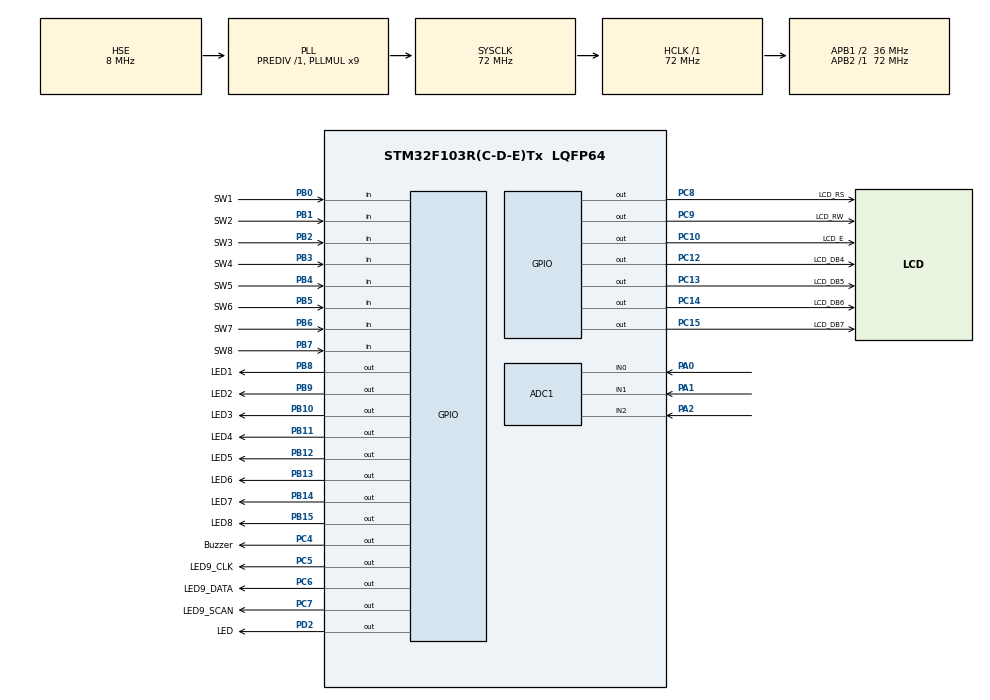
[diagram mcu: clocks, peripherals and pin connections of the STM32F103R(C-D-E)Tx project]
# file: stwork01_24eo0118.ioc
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ADC1.Channel-0\#ChannelRegularConversion=ADC_CHANNEL_0
ADC1.NbrOfConversionFlag=1
ADC1.Rank-0\#ChannelRegularConversion=1
ADC1.SamplingTime-0\#ChannelRegularConversion=ADC_SAMPLETIME_1CYCLE_5
ADC1.master=1
Mcu.Family=STM32F1
Mcu.Name=STM32F103R(C-D-E)Tx
Mcu.Package=LQFP64
NVIC.PriorityGroup=NVIC_PRIORITYGROUP_4
PA0-WKUP.Signal=ADCx_IN0
PA1.Signal=ADCx_IN1
PA13.Mode=Serial_Wire
PA13.Signal=SYS_JTMS-SWDIO
PA14.Mode=Serial_Wire
PA14.Signal=SYS_JTCK-SWCLK
PA2.Signal=ADCx_IN2
PB0.GPIO_Label=SW1
PB0.Signal=GPIO_Input
PB1.GPIO_Label=SW2
PB1.Signal=GPIO_Input
PB10.GPIO_Label=LED3
PB10.Signal=GPIO_Output
PB11.GPIO_Label=LED4
PB11.Signal=GPIO_Output
PB12.GPIO_Label=LED5
PB12.Signal=GPIO_Output
PB13.GPIO_Label=LED6
PB13.Signal=GPIO_Output
PB14.GPIO_Label=LED7
PB14.Signal=GPIO_Output
PB15.GPIO_Label=LED8
PB15.Signal=GPIO_Output
PB2.GPIO_Label=SW3
PB2.Signal=GPIO_Input
PB3.GPIO_Label=SW4
PB3.Signal=GPIO_Input
PB4.GPIO_Label=SW5
PB4.Signal=GPIO_Input
PB5.GPIO_Label=SW6
PB5.Signal=GPIO_Input
PB6.GPIO_Label=SW7
PB6.Signal=GPIO_Input
PB7.GPIO_Label=SW8
PB7.Signal=GPIO_Input
PB8.GPIO_Label=LED1
PB8.Signal=GPIO_Output
PB9.GPIO_Label=LED2
PB9.Signal=GPIO_Output
PC10.GPIO_Label=LCD_E
PC10.Signal=GPIO_Output
PC12.GPIO_Label=LCD_DB4
PC12.Signal=GPIO_Output
PC13-TAMPER-RTC.GPIO_Label=LCD_DB5
PC13-TAMPER-RTC.Signal=GPIO_Output
PC14-OSC32_IN.GPIO_Label=LCD_DB6
PC14-OSC32_IN.Signal=GPIO_Output
PC15-OSC32_OUT.GPIO_Label=LCD_DB7
PC15-OSC32_OUT.Signal=GPIO_Output
PC4.GPIO_Label=Buzzer
PC4.Signal=GPIO_Output
PC5.GPIO_Label=LED9_CLK
PC5.Signal=GPIO_Output
PC6.GPIO_Label=LED9_DATA
PC6.Signal=GPIO_Output
PC7.GPIO_Label=LED9_SCAN
PC7.Signal=GPIO_Output
PC8.GPIO_Label=LCD_RS
PC8.Signal=GPIO_Output
PC9.GPIO_Label=LCD_RW
PC9.Signal=GPIO_Output
PD0-OSC_IN.Mode=HSE-External-Oscillator
PD0-OSC_IN.Signal=RCC_OSC_IN
PD1-OSC_OUT.Mode=HSE-External-Oscillator
PD1-OSC_OUT.Signal=RCC_OSC_OUT
PD2.GPIO_Label=LED
PD2.Signal=GPIO_Output
ProjectManager.HeapSize=0x200
ProjectManager.StackSize=0x400
ProjectManager.TargetToolchain=STM32CubeIDE
RCC.ADCPresc=RCC_ADCPCLK2_DIV6
RCC.AHBFreq_Value=72000000
RCC.APB1CLKDivider=RCC_HCLK_DIV2
RCC.APB1Freq_Value=36000000
RCC.APB1TimFreq_Value=72000000
RCC.APB2Freq_Value=72000000
RCC.APB2TimFreq_Value=72000000
RCC.HCLKFreq_Value=72000000
RCC.PLLMUL=RCC_PLL_MUL9
RCC.PLLSourceVirtual=RCC_PLLSOURCE_HSE
RCC.SYSCLKFreq_VALUE=72000000
RCC.SYSCLKSource=RCC_SYSCLKSOURCE_PLLCLK
RCC.USBFreq_Value=72000000
SH.ADCx_IN0.0=ADC1_IN0,IN0
SH.ADCx_IN1.0=ADC1_IN1,IN1
SH.ADCx_IN2.0=ADC1_IN2,IN2
VP_TIM6_VS_ClockSourceINT.Mode=Enable_Timer
VP_TIM7_VS_ClockSourceINT.Mode=Enable_Timer
board=custom

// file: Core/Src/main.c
/* USER CODE BEGIN Header */
/**
  ******************************************************************************
  * @file           : main.c
  * @brief          : Main program body
  ******************************************************************************
  * @attention
  *
  * Copyright (c) 2024 STMicroelectronics.
  * All rights reserved.
  *
  * This software is licensed under terms that can be found in the LICENSE file
  * in the root directory of this software component.
  * If no LICENSE file comes with this software, it is provided AS-IS.
  *
  ******************************************************************************
  */
/* USER CODE END Header */
#include "main.h"

ADC_HandleTypeDef hadc1;

TIM_HandleTypeDef htim6;
TIM_HandleTypeDef htim7;

void SystemClock_Config(void);
static void MX_GPIO_Init(void);
static void MX_ADC1_Init(void);
static void MX_TIM6_Init(void);
static void MX_TIM7_Init(void);

int main(void)
{

  /* MCU Configuration--------------------------------------------------------*/

  /* Reset of all peripherals, Initializes the Flash interface and the Systick. */
  HAL_Init();

  /* Configure the system clock */
  SystemClock_Config();

  /* Initialize all configured peripherals */
  MX_GPIO_Init();
  MX_ADC1_Init();
  MX_TIM6_Init();
  MX_TIM7_Init();

  /* Infinite loop */
  while (1)
  {

    /* USER CODE BEGIN 3 */
	  //�?�?�?�?�?�?�?�?�?�?�?引数�?ポ�?�ト�??�?�?�?�?�?�?�?�?�?�?�?ピン�?�?�?�?  状�?(Set or Reset)
	  //
	  HAL_GPIO_WritePin(LED1_GPIO_Port, LED1_Pin, !HAL_GPIO_ReadPin(SW8_GPIO_Port, SW8_Pin));
	  HAL_GPIO_WritePin(LED2_GPIO_Port, LED2_Pin, !HAL_GPIO_ReadPin(SW7_GPIO_Port, SW7_Pin));
	  HAL_GPIO_WritePin(LED3_GPIO_Port, LED3_Pin, !HAL_GPIO_ReadPin(SW6_GPIO_Port, SW6_Pin));
	  HAL_GPIO_WritePin(LED4_GPIO_Port, LED4_Pin, !HAL_GPIO_ReadPin(SW5_GPIO_Port, SW5_Pin));
	  HAL_GPIO_WritePin(LED5_GPIO_Port, LED5_Pin, !HAL_GPIO_ReadPin(SW4_GPIO_Port, SW4_Pin));
	  HAL_GPIO_WritePin(LED6_GPIO_Port, LED6_Pin, !HAL_GPIO_ReadPin(SW3_GPIO_Port, SW3_Pin));
	  HAL_GPIO_WritePin(LED7_GPIO_Port, LED7_Pin, !HAL_GPIO_ReadPin(SW2_GPIO_Port, SW2_Pin));
	  HAL_GPIO_WritePin(LED8_GPIO_Port, LED8_Pin, !HAL_GPIO_ReadPin(SW1_GPIO_Port, SW1_Pin));
  }
  /* USER CODE END 3 */
}

void SystemClock_Config(void)
{
  RCC_OscInitTypeDef RCC_OscInitStruct = {0};
  RCC_ClkInitTypeDef RCC_ClkInitStruct = {0};
  RCC_PeriphCLKInitTypeDef PeriphClkInit = {0};

  /** Initializes the RCC Oscillators according to the specified parameters
  * in the RCC_OscInitTypeDef structure.
  */
  RCC_OscInitStruct.OscillatorType = RCC_OSCILLATORTYPE_HSE;
  RCC_OscInitStruct.HSEState = RCC_HSE_ON;
  RCC_OscInitStruct.HSEPredivValue = RCC_HSE_PREDIV_DIV1;
  RCC_OscInitStruct.HSIState = RCC_HSI_ON;
  RCC_OscInitStruct.PLL.PLLState = RCC_PLL_ON;
  RCC_OscInitStruct.PLL.PLLSource = RCC_PLLSOURCE_HSE;
  RCC_OscInitStruct.PLL.PLLMUL = RCC_PLL_MUL9;
  if (HAL_RCC_OscConfig(&RCC_OscInitStruct) != HAL_OK)
  {
    Error_Handler();
  }

  /** Initializes the CPU, AHB and APB buses clocks
  */
  RCC_ClkInitStruct.ClockType = RCC_CLOCKTYPE_HCLK|RCC_CLOCKTYPE_SYSCLK
                              |RCC_CLOCKTYPE_PCLK1|RCC_CLOCKTYPE_PCLK2;
  RCC_ClkInitStruct.SYSCLKSource = RCC_SYSCLKSOURCE_PLLCLK;
  RCC_ClkInitStruct.AHBCLKDivider = RCC_SYSCLK_DIV1;
  RCC_ClkInitStruct.APB1CLKDivider = RCC_HCLK_DIV2;
  RCC_ClkInitStruct.APB2CLKDivider = RCC_HCLK_DIV1;

  if (HAL_RCC_ClockConfig(&RCC_ClkInitStruct, FLASH_LATENCY_2) != HAL_OK)
  {
    Error_Handler();
  }
  PeriphClkInit.PeriphClockSelection = RCC_PERIPHCLK_ADC;
  PeriphClkInit.AdcClockSelection = RCC_ADCPCLK2_DIV6;
  if (HAL_RCCEx_PeriphCLKConfig(&PeriphClkInit) != HAL_OK)
  {
    Error_Handler();
  }
}

static void MX_ADC1_Init(void)
{

  ADC_ChannelConfTypeDef sConfig = {0};

  /** Common config
  */
  hadc1.Instance = ADC1;
  hadc1.Init.ScanConvMode = ADC_SCAN_DISABLE;
  hadc1.Init.ContinuousConvMode = DISABLE;
  hadc1.Init.DiscontinuousConvMode = DISABLE;
  hadc1.Init.ExternalTrigConv = ADC_SOFTWARE_START;
  hadc1.Init.DataAlign = ADC_DATAALIGN_RIGHT;
  hadc1.Init.NbrOfConversion = 1;
  if (HAL_ADC_Init(&hadc1) != HAL_OK)
  {
    Error_Handler();
  }

  /** Configure Regular Channel
  */
  sConfig.Channel = ADC_CHANNEL_0;
  sConfig.Rank = ADC_REGULAR_RANK_1;
  sConfig.SamplingTime = ADC_SAMPLETIME_1CYCLE_5;
  if (HAL_ADC_ConfigChannel(&hadc1, &sConfig) != HAL_OK)
  {
    Error_Handler();
  }

}

static void MX_TIM6_Init(void)
{

  TIM_MasterConfigTypeDef sMasterConfig = {0};

  htim6.Instance = TIM6;
  htim6.Init.Prescaler = 0;
  htim6.Init.CounterMode = TIM_COUNTERMODE_UP;
  htim6.Init.Period = 65535;
  htim6.Init.AutoReloadPreload = TIM_AUTORELOAD_PRELOAD_DISABLE;
  if (HAL_TIM_Base_Init(&htim6) != HAL_OK)
  {
    Error_Handler();
  }
  sMasterConfig.MasterOutputTrigger = TIM_TRGO_RESET;
  sMasterConfig.MasterSlaveMode = TIM_MASTERSLAVEMODE_DISABLE;
  if (HAL_TIMEx_MasterConfigSynchronization(&htim6, &sMasterConfig) != HAL_OK)
  {
    Error_Handler();
  }

}

static void MX_TIM7_Init(void)
{

  TIM_MasterConfigTypeDef sMasterConfig = {0};

  htim7.Instance = TIM7;
  htim7.Init.Prescaler = 0;
  htim7.Init.CounterMode = TIM_COUNTERMODE_UP;
  htim7.Init.Period = 65535;
  htim7.Init.AutoReloadPreload = TIM_AUTORELOAD_PRELOAD_DISABLE;
  if (HAL_TIM_Base_Init(&htim7) != HAL_OK)
  {
    Error_Handler();
  }
  sMasterConfig.MasterOutputTrigger = TIM_TRGO_RESET;
  sMasterConfig.MasterSlaveMode = TIM_MASTERSLAVEMODE_DISABLE;
  if (HAL_TIMEx_MasterConfigSynchronization(&htim7, &sMasterConfig) != HAL_OK)
  {
    Error_Handler();
  }

}

static void MX_GPIO_Init(void)
{
  GPIO_InitTypeDef GPIO_InitStruct = {0};

  /* GPIO Ports Clock Enable */
  __HAL_RCC_GPIOC_CLK_ENABLE();
  __HAL_RCC_GPIOD_CLK_ENABLE();
  __HAL_RCC_GPIOA_CLK_ENABLE();
  __HAL_RCC_GPIOB_CLK_ENABLE();

  /*Configure GPIO pin Output Level */
  HAL_GPIO_WritePin(GPIOC, LCD_DB5_Pin|LCD_DB6_Pin|LCD_DB7_Pin|Buzzer_Pin
                          |LED9_CLK_Pin|LED9_DATA_Pin|LED9_SCAN_Pin|LCD_RS_Pin
                          |LCD_RW_Pin|LCD_E_Pin|LCD_DB4_Pin, GPIO_PIN_RESET);

  /*Configure GPIO pin Output Level */
  HAL_GPIO_WritePin(GPIOB, LED3_Pin|LED4_Pin|LED5_Pin|LED6_Pin
                          |LED7_Pin|LED8_Pin|LED1_Pin|LED2_Pin, GPIO_PIN_RESET);

  /*Configure GPIO pin Output Level */
  HAL_GPIO_WritePin(LED_GPIO_Port, LED_Pin, GPIO_PIN_RESET);

  /*Configure GPIO pins : LCD_DB5_Pin LCD_DB6_Pin LCD_DB7_Pin Buzzer_Pin
                           LED9_CLK_Pin LED9_DATA_Pin LED9_SCAN_Pin LCD_RS_Pin
                           LCD_RW_Pin LCD_E_Pin LCD_DB4_Pin */
  GPIO_InitStruct.Pin = LCD_DB5_Pin|LCD_DB6_Pin|LCD_DB7_Pin|Buzzer_Pin
                          |LED9_CLK_Pin|LED9_DATA_Pin|LED9_SCAN_Pin|LCD_RS_Pin
                          |LCD_RW_Pin|LCD_E_Pin|LCD_DB4_Pin;
  GPIO_InitStruct.Mode = GPIO_MODE_OUTPUT_PP;
  GPIO_InitStruct.Pull = GPIO_NOPULL;
  GPIO_InitStruct.Speed = GPIO_SPEED_FREQ_LOW;
  HAL_GPIO_Init(GPIOC, &GPIO_InitStruct);

  /*Configure GPIO pins : SW1_Pin SW2_Pin SW3_Pin SW4_Pin
                           SW5_Pin SW6_Pin SW7_Pin SW8_Pin */
  GPIO_InitStruct.Pin = SW1_Pin|SW2_Pin|SW3_Pin|SW4_Pin
                          |SW5_Pin|SW6_Pin|SW7_Pin|SW8_Pin;
  GPIO_InitStruct.Mode = GPIO_MODE_INPUT;
  GPIO_InitStruct.Pull = GPIO_NOPULL;
  HAL_GPIO_Init(GPIOB, &GPIO_InitStruct);

  /*Configure GPIO pins : LED3_Pin LED4_Pin LED5_Pin LED6_Pin
                           LED7_Pin LED8_Pin LED1_Pin LED2_Pin */
  GPIO_InitStruct.Pin = LED3_Pin|LED4_Pin|LED5_Pin|LED6_Pin
                          |LED7_Pin|LED8_Pin|LED1_Pin|LED2_Pin;
  GPIO_InitStruct.Mode = GPIO_MODE_OUTPUT_PP;
  GPIO_InitStruct.Pull = GPIO_NOPULL;
  GPIO_InitStruct.Speed = GPIO_SPEED_FREQ_LOW;
  HAL_GPIO_Init(GPIOB, &GPIO_InitStruct);

  /*Configure GPIO pin : LED_Pin */
  GPIO_InitStruct.Pin = LED_Pin;
  GPIO_InitStruct.Mode = GPIO_MODE_OUTPUT_PP;
  GPIO_InitStruct.Pull = GPIO_NOPULL;
  GPIO_InitStruct.Speed = GPIO_SPEED_FREQ_LOW;
  HAL_GPIO_Init(LED_GPIO_Port, &GPIO_InitStruct);

}

void Error_Handler(void)
{
  __disable_irq();
  while (1)
  {
  }
}
